# DP32G030 register map
File version: 1.0
CPU: CM0 r0p0, little endian, no MPU, no FPU, 4 interrupt priority bits
Registers are 32-bit, read-write, reset 0x0 unless marked. A register's access mark holds for its fields unless they carry their own. Offsets are from the block's base; [hi:lo] are bit positions.

## TIMER_PLUS0 — TIMER_PLUS0 unit
Base 0x40067000
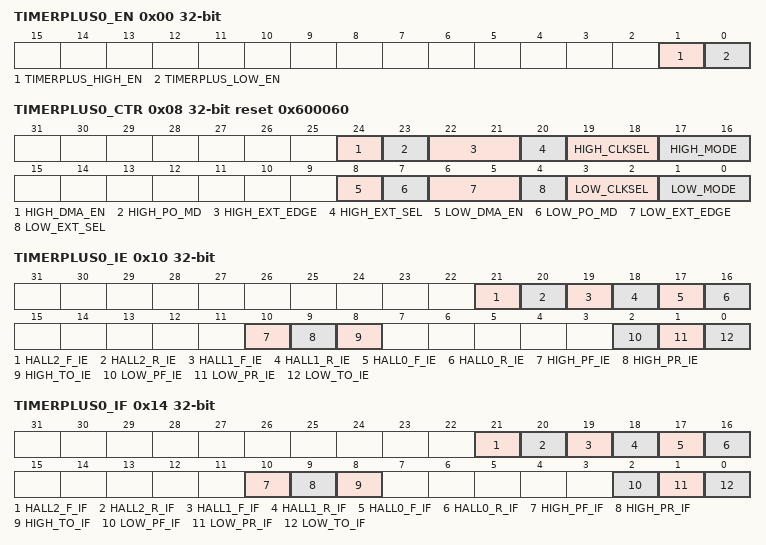
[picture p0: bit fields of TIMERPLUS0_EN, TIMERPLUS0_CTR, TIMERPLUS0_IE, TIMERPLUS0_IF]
0x00 TIMERPLUS0_EN — TIMERPLUS enable register
  [1] TIMERPLUS_HIGH_EN — TIMERPLUS High 16bit Timer Enable Register 0: Forbidden Energy 1: Enabling
  [0] TIMERPLUS_LOW_EN — TIMERPLUS Low 16bit Timer Enable Register 0: Forbidden Energy 1: Enabling
0x04 TIMERPLUS0_DIV — TIMERPLUS Count Clock Prescaler Register
  [15:0] TIMERPLUS_DIV — TIMERPLUS Count Clock Divider Register 0x0000: indicates 1 division 0x0001: indicates 2 divisions ...... 0xFFFF: indicates 65536 division frequency
0x08 TIMERPLUS0_CTR reset 0x600060 — TIMERPLUS configuration register
  [24] HIGH_DMA_EN — DMA Read TIMER HIGH Capture Value Enable 0: CPU reads the captured value 1: DMA Read Capture Value
  [23] HIGH_PO_MD — TIMER HIGH Periodic Pulse Output Enable 0: Output off 1: Output enable
  [22:21] HIGH_EXT_EDGE — TIMER HIGH Count mode or input capture mode input signal active edge selection 00: Rising edge active 01: Falling edge active 10: Rising or falling edge valid
  [20] HIGH_EXT_SEL — TIMER HIGH Count mode or input capture mode input signal selection 0: timer_in0 1: timer_in1
  [19:18] HIGH_CLKSEL — TIMER HIGH Count Clock Source Selection 00: PCLK/PREDIV (selects pclk pre-divided clock) 01: CNTSRC0 10: CNTSRC1
  [17:16] HIGH_MODE — TIMER HIGH Operating Mode Register 00: Timing mode (can generate periodic pulse output signal) 01: Count mode (only pclk can be selected for count clock) 10: Input capture mode
  [8] LOW_DMA_EN — DMA Read TIMER LOW Capture Value Enable 0: CPU reads the captured value 1: DMA Read Capture Value
  [7] LOW_PO_MD — TIMER LOW Periodic Pulse Output Enable 0: Output off 1: Output enable
  [6:5] LOW_EXT_EDGE — TIMER LOW Count mode or input capture mode Input signal active edge selection 00: Rising edge active 01: Falling edge active 10: Rising or falling edge valid
  [4] LOW_EXT_SEL — TIMER LOW Count Mode or Input Capture Mode Input Signal Selection 0: timer_in0 1: timer_in1
  [3:2] LOW_CLKSEL — TIMER LOW Count Clock Source Selection 00: PCLK/PREDIV (selects pclk pre-divided clock) 01: CNTSRC0 10: CNTSRC1
  [1:0] LOW_MODE — TIMER LOW Operating Mode Register 00: Timing mode (can generate periodic pulse output signal) 01: Count mode (only pclk can be selected for count clock) 10: Input capture mode 11: HALL mode
0x10 TIMERPLUS0_IE — TIMERPLUS interrupt enable register
  [21] HALL2_F_IE — HALL2 Falling edge interrupt enable
  [20] HALL2_R_IE — HALL2 rising edge interrupt enable
  [19] HALL1_F_IE — HALL1 Falling edge interrupt enable
  [18] HALL1_R_IE — HALL1 rising edge interrupt enable
  [17] HALL0_F_IE — HALL0 Falling edge interrupt enable
  [16] HALL0_R_IE — HALL0 rising edge interrupt enable
  [10] HIGH_PF_IE — TIMERPLUS HIGH Input pulse falling edge interrupt enable
  [9] HIGH_PR_IE — TIMERPLUS HIGH Input pulse rising edge interrupt enable
  [8] HIGH_TO_IE — TIMERPLUS HIGH Reach target value interrupt enable
  [2] LOW_PF_IE — TIMERPLUS LOW Input pulse falling edge interrupt enable
  [1] LOW_PR_IE — TIMERPLUS LOW Input pulse rising edge interrupt enable
  [0] LOW_TO_IE — TIMERPLUS LOW Reach target value interrupt enable
0x14 TIMERPLUS0_IF — TIMERPLUS Interrupt Status Register
  [21] HALL2_F_IF write-1-clears — HALL2 Falling edge interrupt status write 1 clear
  [20] HALL2_R_IF write-1-clears — HALL2 Rising edge interrupt status write 1 clear
  [19] HALL1_F_IF write-1-clears — HALL1 Falling edge interrupt status write 1 clear
  [18] HALL1_R_IF write-1-clears — HALL1 Rising edge interrupt status write 1 clear
  [17] HALL0_F_IF write-1-clears — HALL0 Falling edge interrupt status write 1 clear
  [16] HALL0_R_IF write-1-clears — HALL0 Rising edge interrupt status write 1 clear
  [10] HIGH_PF_IF write-1-clears — TIMERPLUS HIGH Input pulse falling edge interrupt status write 1 clear
  [9] HIGH_PR_IF write-1-clears — TIMERPLUS HIGH Input pulse rising edge interrupt status write 1 clear
  [8] HIGH_TO_IF write-1-clears — TIMERPLUS HIGH Reach target value Interrupt status write 1 clear
  [2] LOW_PF_IF write-1-clears — TIMERPLUS LOW Input pulse falling edge interrupt status write 1 clear
  [1] LOW_PR_IF write-1-clears — TIMERPLUS LOW Input pulse rising edge interrupt status write 1 clear
  [0] LOW_TO_IF write-1-clears — TIMERPLUS LOW Reach target value Interrupt status write 1 clear
0x20 TIMERPLUS0_HIGH_GOAL reset 0xFFFF — TIMERPLUS HIGH target configuration register
  [15:0] HIGH_LOAD — TIMERPLUS HIGH Timer Target Configuration Register When the high 16bit counter counts up to the set value, the corresponding status signal is generated.
0x24 TIMERPLUS0_HIGH_CNT ro — TIMERPLUS HIGH Current count value register
  [15:0] HIGH_CNT — TIMERPLUS HIGH Timer Current Count Value
0x28 TIMERPLUS0_HIGH_CVAL ro — TIMERPLUS HIGH capture value register
  [15:0] HIGH_CVAL — TIMERPLUS HIGH Capture value count value
0x30 TIMERPLUS0_LOW_GOAL reset 0xFFFF — TIMERPLUS LOW target configuration register
  [15:0] LOW_LOAD — TIMERPLUS LOW Timer Target Configuration Register When the low 16bit counter counts up to the set value, the corresponding status signal is generated.
0x34 TIMERPLUS0_LOW_CNT ro — TIMERPLUS LOW Current count value register
  [15:0] LOW_CNT — TIMERPLUS LOW Timer Current Count Value
0x38 TIMERPLUS0_LOW_CVAL ro — TIMERPLUS HIGH capture value register
  [15:0] LOW_CVAL — TIMERPLUS LOW Capture value count value
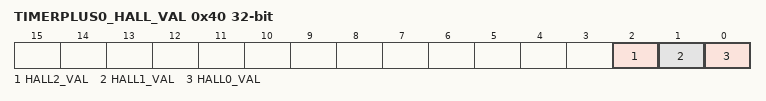
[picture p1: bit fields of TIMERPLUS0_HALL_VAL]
0x40 TIMERPLUS0_HALL_VAL ro — HALL Signal Raw Value Register
  [2] HALL2_VAL — Raw signal level of HALL2
  [1] HALL1_VAL — Raw signal level of HALL1
  [0] HALL0_VAL — Raw signal level of HALL0
